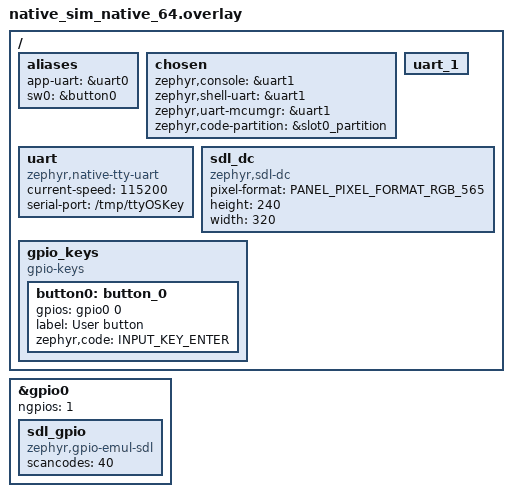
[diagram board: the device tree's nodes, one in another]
#include <zephyr/dt-bindings/input/input-event-codes.h>

/ {
	aliases {
		app-uart = &uart0;
		sw0 = &button0;
	};
	chosen {
		zephyr,console = &uart1;
		zephyr,shell-uart = &uart1;
		zephyr,uart-mcumgr = &uart1;
		zephyr,code-partition = &slot0_partition;
	};

	uart {
		status = "okay";
		compatible = "zephyr,native-tty-uart";
		current-speed = <115200>;
		serial-port = "/tmp/ttyOSKey";
	};

	uart_1 {
		status = "okay";
	};

	sdl_dc {
		compatible = "zephyr,sdl-dc";
		pixel-format = <PANEL_PIXEL_FORMAT_RGB_565>;
		height = < 240 >;
		width = < 320 >;
	};

	gpio_keys {
		compatible = "gpio-keys";
		button0: button_0 {
			gpios = <&gpio0 0 GPIO_ACTIVE_HIGH>;
			label = "User button";
			zephyr,code = <INPUT_KEY_ENTER>;
		};
	};
};

&gpio0 {
	ngpios = <1>;
	sdl_gpio {
		compatible = "zephyr,gpio-emul-sdl";
		scancodes = <40>;
	};
};
